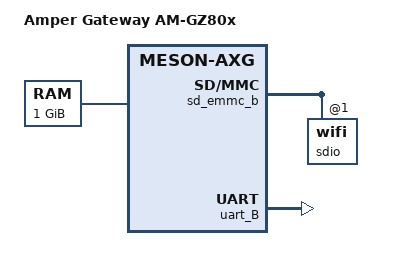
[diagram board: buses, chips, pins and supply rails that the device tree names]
// SPDX-License-Identifier: (GPL-2.0+ OR MIT)
/*
 * Copyright (c) 2024 Patrick Yavitz <pyavitz@armbian.com>
 */

/dts-v1/;

#include "meson-axg-amper-gateway-gz80x.dtsi"

/ {
	compatible = "amper,gateway-am-gz80x", "amlogic,a113x", "amlogic,meson-axg";
	model = "Amper Gateway AM-GZ80x";

	aliases {
		serial1 = &uart_B;
		serial2 = &uart_AO_B;
		ethernet0 = &ethmac;
	};

	/* 1024MB RAM */
	memory@0 {
		device_type = "memory";
		reg = <0x0 0x0 0x0 0x40000000>;
	};
};

&sd_emmc_b {
	sdio: wifi@1 {
		reg = <1>;
	};
};

&uart_B {
	status = "okay";
	pinctrl-0 = <&uart_b_z_pins>;
	pinctrl-names = "default";
};
